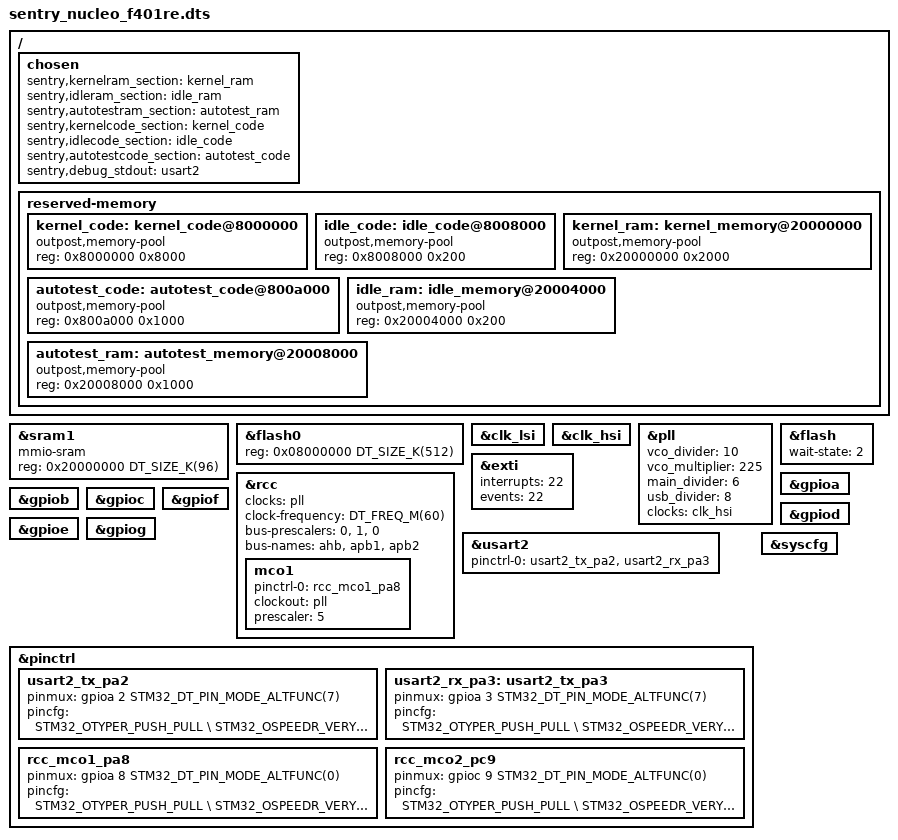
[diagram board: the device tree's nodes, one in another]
/*
 * Copyright (c) 2023,Ledger SAS
 *
 * SPDX-License-Identifier: Apache-2.0
 */

/dts-v1/;

#include <st/f4/stm32f401.dtsi>
#include <dt-bindings/pinctrl/stm32-pinctrl.h>

/{
	chosen {
		sentry,kernelram_section = <&kernel_ram>;
		sentry,idleram_section = <&idle_ram>;
		sentry,autotestram_section = <&autotest_ram>;
		sentry,kernelcode_section = <&kernel_code>;
		sentry,idlecode_section = <&idle_code>;
		sentry,autotestcode_section = <&autotest_code>;
		sentry,debug_stdout = <&usart2>;
	};

	reserved-memory {
		#address-cells = <1>;
		#size-cells = <1>;

		kernel_code: kernel_code@8000000 {
        	reg = <0x8000000 0x8000>;
			compatible = "outpost,memory-pool";
    	};
		idle_code: idle_code@8008000 {
        	reg = <0x8008000 0x200>;
			compatible = "outpost,memory-pool";
    	};
		autotest_code: autotest_code@800a000 {
			reg = <0x800a000 0x1000>;
			compatible = "outpost,memory-pool";
		};

		kernel_ram: kernel_memory@20000000 {
        	reg = <0x20000000 0x2000>;
			compatible = "outpost,memory-pool";
    	};

    	idle_ram: idle_memory@20004000 {
        	reg = <0x20004000 0x200>;
			compatible = "outpost,memory-pool";
    	};
		autotest_ram: autotest_memory@20008000 {
        	reg = <0x20008000 0x1000>;
			compatible = "outpost,memory-pool";
    	};
	};
};

&sram1 {
	compatible = "mmio-sram";
	reg = <0x20000000 DT_SIZE_K(96)>;
};

&flash0 {
	reg = <0x08000000 DT_SIZE_K(512)>;
};

&clk_lsi {
	status = "okay";
};

&clk_hsi {
	status = "okay";
};

&pll {
	vco_divider = <10>;
	vco_multiplier = <225>;
	main_divider = <6>;
	usb_divider = <8>;
	clocks = <&clk_hsi>;
	status = "okay";
};

&flash {
	wait-state = <2>; /* According to voltage supply and sysclock */
	status = "okay";
};

&rcc {
	clocks = <&pll>;
	clock-frequency = <DT_FREQ_M(60)>;
	bus-prescalers = <0>, <1>, <0>;
	bus-names = "ahb", "apb1", "apb2";
	status = "okay";

	mco1 {
		pinctrl-0 = <&rcc_mco1_pa8>;
		clockout = <&pll>; /* XXX use reg value from svd */
		prescaler = <5>;
		status = "okay";
	};
};

&exti {
	interrupts = <22>;
	events = <22>;
	status = "okay";
};

&gpioa {
	status = "okay";
};

&gpiob {
	status = "okay";
};

&gpioc {
	status = "okay";
};

&gpiod {
	status = "okay";
};

&gpioe {
	status = "okay";
};

&gpiof {
	status = "okay";
};

&gpiog {
	status = "okay";
};

&usart2 {
    status = "okay";
	pinctrl-0 = <&usart2_tx_pa2>, <&usart2_rx_pa3>;
};

&pinctrl {
	usart2_tx_pa2: usart2_tx_pa2  {
		pinmux = <&gpioa 2 STM32_DT_PIN_MODE_ALTFUNC(7)>;
		pincfg = <STM32_OTYPER_PUSH_PULL \
				  STM32_OSPEEDR_VERY_HIGH_SPEED \
				  STM32_PUPDR_NO_PULL>;
	};

	usart2_rx_pa3: usart2_tx_pa3  {
		pinmux = <&gpioa 3 STM32_DT_PIN_MODE_ALTFUNC(7)>;
		pincfg = <STM32_OTYPER_PUSH_PULL \
				  STM32_OSPEEDR_VERY_HIGH_SPEED \
				  STM32_PUPDR_NO_PULL>;
	};

	rcc_mco1_pa8: rcc_mco1_pa8  {
		pinmux = <&gpioa 8 STM32_DT_PIN_MODE_ALTFUNC(0)>;
		pincfg = <STM32_OTYPER_PUSH_PULL \
				  STM32_OSPEEDR_VERY_HIGH_SPEED \
				  STM32_PUPDR_NO_PULL>;
	};

	rcc_mco2_pc9: rcc_mco2_pc9 {
		pinmux = <&gpioc 9 STM32_DT_PIN_MODE_ALTFUNC(0)>;
		pincfg = <STM32_OTYPER_PUSH_PULL \
				  STM32_OSPEEDR_VERY_HIGH_SPEED \
				  STM32_PUPDR_NO_PULL>;
	};
};

&syscfg {
	status = "okay";
};
